# MCXN947_cm33_core0 register map
Vendor: nxp.com; File version: 1.0
CPU: CM33 r2p0, little endian, MPU, FPU, VTOR, 3 interrupt priority bits
Registers are 32-bit, read-write, reset 0x0 unless marked. A register's access mark holds for its fields unless they carry their own. Offsets are from the block's base; [hi:lo] are bit positions; {n}, {i} and the like mark numbered series.

## FMU0 — Flash
Base 0x40043000
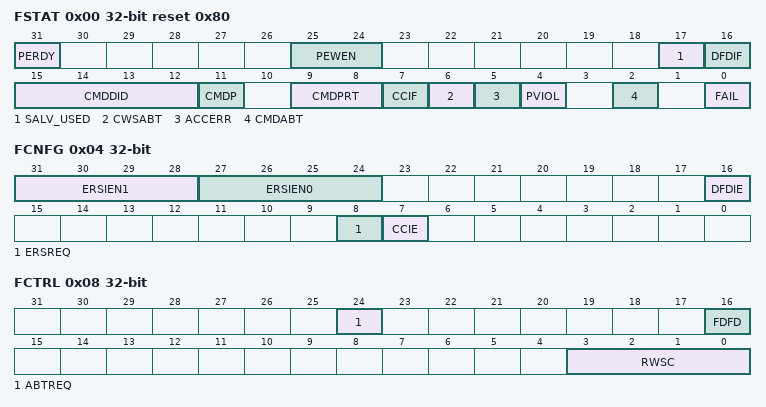
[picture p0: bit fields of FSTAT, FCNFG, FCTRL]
0x00 FSTAT reset 0x80 (reset mask 0xFFFFFFFE) — Flash Status Register
  [31] PERDY write-1-clears — Program-Erase Ready Control/Status Flag
    0=Program or sector erase command operation not stalled; 1=Program or sector erase command operation ready to execute
  [25:24] PEWEN ro — Program-Erase Write Enable Control
    0=Writes are not enabled; 1=Writes are enabled for one flash or IFR phrase (phrase programming, sector erase); 2=Writes are enabled for one flash or IFR page (page programming)
  [17] SALV_USED ro — Salvage Used for Erase operation
    0=Salvage not used during last operation; 1=Salvage used during the last erase operation
  [16] DFDIF write-1-clears — Double Bit Fault Detect Interrupt Flag
    0=Double bit fault not detected during a valid flash read access; 1=Double bit fault detected (or FCTRL[FDFD] is set) during a valid flash read access
  [15:12] CMDDID ro — Command domain ID
  [11] CMDP ro — Command protection status flag
    0=Command protection level and domain ID are stale; 1=Command protection level (CMDPRT) and domain ID (CMDDID) are set
  [9:8] CMDPRT ro — Command protection level
    0=Secure, normal access; 1=Secure, privileged access; 2=Nonsecure, normal access; 3=Nonsecure, privileged access
  [7] CCIF write-1-clears — Command Complete Interrupt Flag
    0=Flash command, initialization, or power mode recovery in progress; 1=Flash command, initialization, or power mode recovery has completed
  [6] CWSABT write-1-clears — Command Write Sequence Abort Flag
    0=Command write sequence not aborted; 1=Command write sequence aborted
  [5] ACCERR write-1-clears — Command Access Error Flag
    0=No access error detected; 1=Access error detected
  [4] PVIOL write-1-clears — Command Protection Violation Flag
    0=No protection violation detected; 1=Protection violation detected
  [2] CMDABT write-1-clears — Command Abort Flag
    0=No command abort detected; 1=Command abort detected
  [0] FAIL ro — Command Fail Flag
    0=Error not detected; 1=Error detected
0x04 FCNFG (reset mask 0xFFFFFF) — Flash Configuration Register
  [31:28] ERSIEN1 ro — Erase IFR Sector Enable - Block 1 (for dual block configs)
    0=Block 1 IFR Sector X is protected from erase by ERSSCR command; 1=Block 1 IFR Sector X is not protected from erase by ERSSCR command
  [27:24] ERSIEN0 ro — Erase IFR Sector Enable - Block 0
    0=Block 0 IFR Sector X is protected from erase by ERSSCR command; 1=Block 0 IFR Sector X is not protected from erase by ERSSCR command
  [16] DFDIE — Double Bit Fault Detect Interrupt Enable
    0=Double bit fault detect interrupt disabled; 1=Double bit fault detect interrupt enabled
  [8] ERSREQ ro — Mass Erase Request
    0=No request or request complete; 1=Request to run the Mass Erase operation
  [7] CCIE — Command Complete Interrupt Enable
    0=Command complete interrupt disabled; 1=Command complete interrupt enabled
0x08 FCTRL (reset mask 0xFFFFFFF0) — Flash Control Register
  [24] ABTREQ — Abort Request
    0=No request to abort a command write sequence; 1=Request to abort a command write sequence
  [16] FDFD — Force Double Bit Fault Detect
    0=FSTAT[DFDIF] sets only if a double bit fault is detected during a valid flash read access from the platform flash controller; 1=FSTAT[DFDIF] sets during any valid flash read access from the platform flash controller. An interrupt request is generated if the DFDIE bit is set.
  [3:0] RWSC — Read Wait-State Control
{0x10+4i} FCCOB{i} (i=0..7) — Flash Common Command Object Registers
  [31:0] CCOBn

## OSTIMER0 — OSTIMER
Base 0x40049000
0x00 EVTIMERL ro — EVTIMER Low
  [31:0] EVTIMER_COUNT_VALUE
0x04 EVTIMERH ro — EVTIMER High
  [9:0] EVTIMER_COUNT_VALUE
0x08 CAPTURE_L ro — Local Capture Low for CPU
  [31:0] CAPTURE_VALUE — EVTimer Capture Value
0x0C CAPTURE_H ro — Local Capture High for CPU
  [9:0] CAPTURE_VALUE — EVTimer Capture Value
0x10 MATCH_L reset 0xFFFFFFFF — Local Match Low for CPU
  [31:0] MATCH_VALUE — EVTimer Match Value
0x14 MATCH_H reset 0xFFFFFFFF — Local Match High for CPU
  [9:0] MATCH_VALUE — EVTimer Match Value
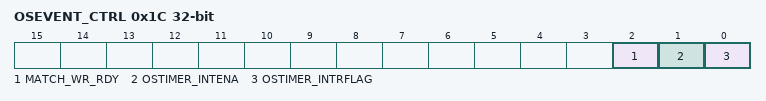
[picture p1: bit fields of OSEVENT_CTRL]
0x1C OSEVENT_CTRL — OSTIMER Control for CPU
  [2] MATCH_WR_RDY — EVTimer Match Write Ready
  [1] OSTIMER_INTENA — Interrupt or Wake-Up Request
    0=INTERRUPTS_BLOCKED; 1=INTERRUPTS_ENABLED
  [0] OSTIMER_INTRFLAG write-1-clears — Interrupt Flag
